# CY8C5868AXI_LP032 register map
File version: 0.1
Registers are 8-bit, read-write, no defined reset value unless marked. A register's access mark holds for its fields unless they carry their own. Offsets are from the block's base; [hi:lo] are bit positions; {n}, {i} and the like mark numbered series.

## BoostConv
Base 0x40004320
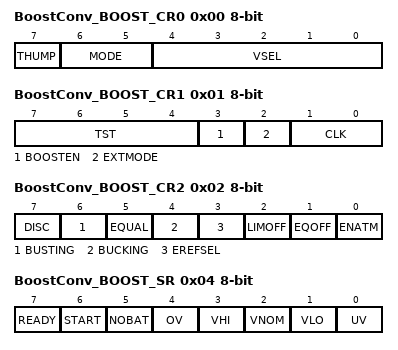
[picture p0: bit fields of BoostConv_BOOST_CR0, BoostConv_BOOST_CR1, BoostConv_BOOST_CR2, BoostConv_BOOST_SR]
0x00 BoostConv_BOOST_CR0 — Boost Control Register 0
  [7] THUMP — Generate a 1us pulse on 0->1 transition
    0=Doesn't generate a 1us pulse on 0->1 transition; 1=Generate a 1us pulse on 0->1 transition
  [6:5] MODE — Boost mode select
    1=MODE_STANDBY (Standby mode); 3=MODE_ACTIVE (Active mode)
  [4:0] VSEL — Boost voltage selection
    0=VSEL_OFF (Off (0V)); 3=VSEL_1P80V (1.80V (Default when {Vint1,Vint0} == 2'b01)); 4=VSEL_1P90V (1.90V); 5=VSEL_2P00V (2.00V); 6=VSEL_2P10V (2.10V); 7=VSEL_2P20V (2.20V); 8=VSEL_2P30V (2.30V); 9=VSEL_2P40V (2.40V); 10=VSEL_2P50V (2.50V); 11=VSEL_2P60V (2.60V); 12=VSEL_2P70V (2.70V (Default when {Vint1,Vint0} == 2'b10)); 13=VSEL_2P80V (2.80V); 14=VSEL_2P90V (2.90V); 15=VSEL_3P00V (3.00V); 16=VSEL_3P10V (3.10V); 17=VSEL_3P20V (3.20V); 18=VSEL_3P30V (3.30V (Default when {Vint1,Vint0} == 2'b11)); 19=VSEL_3P40V (3.40V); 20=VSEL_3P50V (3.50V); 21=VSEL_3P60V (3.60V); 22=VSEL_4P00V (4.00V - Schottky diode req'd); 23=VSEL_4P25V (4.25V - Schottky diode req'd); 24=VSEL_4P50V (4.50V - Schottky diode req'd); 25=VSEL_4P75V (4.75V - Schottky diode req'd); 26=VSEL_5P00V (5.00V - Schottky diode req'd); 27=VSEL_5P25V (5.25V - Schottky diode req'd)
0x01 BoostConv_BOOST_CR1 — Boost Control Register 1
  [7:4] TST — Test mode for IV char of drive transistors. Setting tst[0] also inhibits discontinuous operation
    0=TST_OFF (Test mode off); 4=TST_WE_NMOS (NMOS on (weak)); 5=TST_ST_NMOS (NMOS on (strong)); 6=TST_WE_PMOS (PMOS on (weak)); 7=TST_ST_PMOS (PMOS on (strong))
  [3] BOOSTEN — When set, enables boost operation
    0=Disables_boost_operation; 1=Enables_boost_operation
  [2] EXTMODE — When set, enables mode control from xmode[1:0] instead of control register 1
    0=Disables mode control from xmode[1:0] instead of control register 1; 1=Enables mode control from xmode[1:0] instead of control register 1
  [1:0] CLK — Boost clock frequency
    0=CLK_2MHZ (2.0 MHz); 1=CLK_500KHZ (0.4 MHz); 2=CLK_125KHZ (0.1 MHz); 3=CLK_EXT (External)
0x02 BoostConv_BOOST_CR2 — Boost Control Register 2
  [7] DISC — When set, boost converter is operating in discontinuous mode
    0=Boost_converter_isn_t_operating_in_discontinuous_mode; 1=Boost_converter_is_operating_in_discontinuous_mode
  [6] BUSTING — When set, converter is boosting
    0=Converter_bypassed; 1=Converter_is_boosting
  [5] EQUAL — When set, converter is bypassed. Vin connected to Vout
    0=Converter_boosting; 1=Converter is bypassed (Vin=Vsel). Vin connected to Vout
  [4] BUCKING — When set, converter is bucking. This is always 0 for boost only converters.
    0=Boost_only_converters; 1=Converter_is_bucking
  [3] EREFSEL — When set, selects external reference
    0=BOOST_EREFSEL_INTERNAL (Select internal reference); 1=BOOST_EREFSEL_EXTERNAL (Select external 800mv precision reference (vref_800mv))
  [2] LIMOFF — When set, turns off skip cycle current limiter
    0=Turns_on_skip_cycle_current_limiter; 1=Turns_off_skip_cycle_current_limiter
  [1] EQOFF — When set, disables auto battery connect to output when Vin=Vsel
    0=Enables_auto_battery_connect_to_output_when_Vin_Vsel; 1=Disables_auto_battery_connect_to_output_when_Vin_Vsel
  [0] ENATM — When set, enables automatic standby regulator
    0=Disables_automatic_standby_regulator; 1=Enables_automatic_standby_regulator
0x03 BoostConv_BOOST_CR3 — Boost Control Register 3
  [7:0] PWM — PWM value should not be written during normal operation
    0=pwm_7_0_ (Boost PWM value (should not be written during normal operation))
0x04 BoostConv_BOOST_SR — Boost Status Register
  [7] READY — When set, internal circuits have been initialized
    0=Internal_circuits_not_initialized (Internal circuits have not been initialized); 1=Internal_circuits_initialized (Internal circuits have been initialized)
  [6] START — When set, converter is in startup mode
    0=Converter_is_not_in_startup_mode; 1=Converter_is_in_startup_mode
  [5] NOBAT — When set, battery input is grounded (no battery present)
    0=Battery_input_is_not_grounded; 1=Battery input is grounded (no battery present)
  [4] OV — Output above overvoltage limit when 1, below limit when 0
    0=Output is below overvoltage limit; 1=Output is above overvoltage limit
  [3] VHI — Output is above vhigh limit when 1, below limit when 0
    0=Output is below vhigh limit; 1=Output is above vhigh limit
  [2] VNOM — Output is above nominal when 1, below nominal when 0
    0=Output_is_below_nominal; 1=Output_is_above_nominal
  [1] VLO — Output is above vlow limit when 1, below limit when 0
    0=Output is below vlow limit; 1=Output is above vlow limit
  [0] UV — Output is above undervoltage limit when 1, below limit when 0
    0=Output is below undervoltage limit; 1=Output is above undervoltage limit
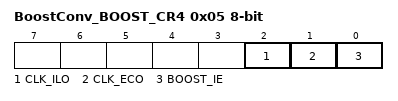
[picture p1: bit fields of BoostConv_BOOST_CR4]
0x05 BoostConv_BOOST_CR4 — Boost Control Register 4
  [2] CLK_ILO ro — When set, 32k ILO is connected to boost external clock instead of 32k crystal oscillator. To prevent collision, user needs to make sure that crystal oscillator source is turned off
    0=32k_ILO_not_connected (32k ILO isn't connected to boost external clock instead of 32k crystal oscillator); 1=32k ILO is connected to boost external clock instead of 32k crystal oscillator
  [1] CLK_ECO ro — When set, 32k crystal oscillator is connected to boost external clock instead of 32k ILO. To prevent collision, user needs to make sure that clk_ilo source is turned off.
    0=32k_crystal_oscillator_not_connected (32k crystal oscillator isn't connected to boost external clock instead of 32k ILO); 1=32k crystal oscillator is connected to boost external clock instead of 32k ILO
  [0] BOOST_IE ro — When set, a boost undervoltage condition is propagated to the interrupt controller via the PM interrupt line. When clear, the interrupt condition is masked.
    0=The_interrupt_condition_is_masked; 1=Boost_undervoltage_condition_is_propagated_to_the_interrupt_controller_via_the_PM_________________________interrupt_line
0x06 BoostConv_BOOST_SR2 — Boost Status Register 2
  [0] BOOST_INT — When set, a boost undervoltage event has occured. The setting of limact_ie determines whether this interrupt condition is masked or propagated to the interrupt controller.
    0=Boost_undervoltage_event_has_not_occured; 1=Boost_undervoltage_event_has_occured
